# cslr_usb_001 register map
Vendor: Texas Instruments
Registers are 32-bit, access not given, reset values left out (the file's numbers can be read two ways) unless marked. A register's access mark holds for its fields unless they carry their own. Offsets are as the file gives them; [hi:lo] are bit positions; {n}, {i} and the like mark numbered series; 'fields as' and 'values as' point back to an identical list.

## USB (part 2 of 2) — USB2.0 OTG Controller
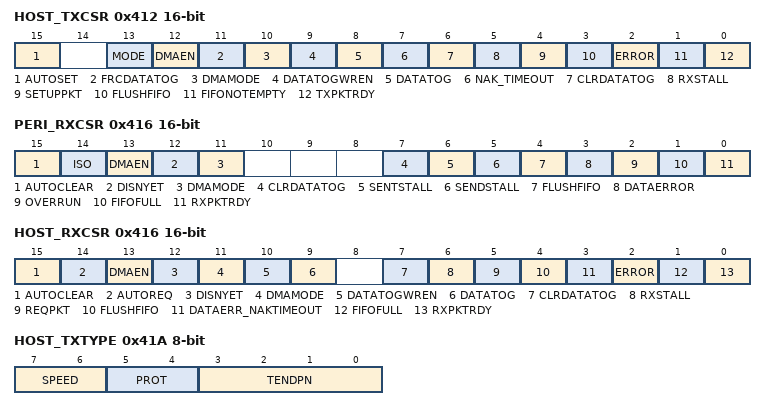
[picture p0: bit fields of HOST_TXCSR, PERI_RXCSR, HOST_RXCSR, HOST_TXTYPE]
0x412 HOST_TXCSR 16-bit — Control Status register for host Tx endpoint. (Index register set to select Endpoints 1 - 4)
  [15] AUTOSET rw — When this bit is set, TXPKTRDY will be automatically set when data of the maximum packet size (value in TXMAXP) is loaded into the Tx FIFO. If a packet of less than the maximum packet size is loaded, then TXPKTRDY will have to be set manually. TXPKTRDY will also be automatically set when the first of two packets in the Tx FIFO has been sent and the second packet is the maximum packet size
  [13] MODE rw — Set this bit to enable the endpoint direction as Tx, and clear the bit to enable it as Rx Note: This bit has any effect only where the same endpoint FIFO is used for both Tx and Rx transactions
  [12] DMAEN rw — Set this bit to enable the DMA request for the Tx endpoint
  [11] FRCDATATOG rw — Set this bit to force the endpoint data toggle to switch and the data packet to be cleared from the FIFO, regardless of whether an ACK was received. This can be used by Interrupt Tx endpoints that are used to communicate rate feedback for Isochronous endpoints
  [10] DMAMODE rw — This bit should always be 0
  [9] DATATOGWREN wo — Write 1 to this bit to enable the DATATOG bit to be written. This bit is automatically cleared once the new value is written to DATATOG
  [8] DATATOG rw — When read, this bit indicates the current state of the Tx EP data toggle. If DATATOGWREN is high, this bit canbe written with the required setting of the data toggle. If DATATOGWREN is low, any value written to this bit is ignored
  [7] NAK_TIMEOUT rw — This bit will be set when the Tx endpoint is halted following the receipt of NAK responses for longer than the time set as the NAKLIMIT by the TXINTERVAL register. It should be cleared to allow the endpoint to continue Note: Valid only for Bulk endpoints
  [6] CLRDATATOG wo — Write a 1 to this bit to reset the endpoint data toggle to 0
  [5] RXSTALL rw — This bit is set when a STALL handshake is received. The FIFO is flushed and the TXPKTRDY bit is cleared (see below). The user should clear this bit
  [4] SETUPPKT rw — Set this bit at the sametime as TXPKTRDY is set, to send a SETUP token instead of an OUT token for the transaction. Note: Setting this bit also clears DATATOG bit
  [3] FLUSHFIFO wo — Write a 1 to this bit to flush the next packet to be transmitted from the endpoint Tx FIFO. The FIFO pointer is reset and the TXPKTRDY bit (below) is cleared. Note: FlushFIFO has no effect unless TXPKTRDY is set. Also note that, if the FIFO is double-buffered, FLUSHFIFO may need to be set twice to completely clear the FIFO
  [2] ERROR rw — The USB controller sets this bit when 3 attempts have been made to send a packet and no handshake packet has been received. The user should clear this bit. An interrupt is generated when the bit is set Valid only when the endpoint is operating in Bulk or Interrupt mode
  [1] FIFONOTEMPTY rw — The USB controller sets this bit when there is at least 1 packet in the Tx FIFO
  [0] TXPKTRDY rw — Set this bit after loading a data packet into the FIFO. It is cleared automatically when a data packet has been transmitted. An interrupt is generated (if enabled) when the bit is cleared
0x414 RXMAXP 16-bit — Maximum packet size for peripheral/host Rx endpoint (Index register set to select Endpoints 1 - 4 only)
  [10:0] MAXPAYLOAD rw — Defines the maximum amount of data that can be transferred through the selected Rx endpoint in a single frame / microframe (High-speed transfers) The value set can be up to 1024 bytes but is subject to the constraints placed by the USB Specification on packet sizes for Bulk, Interrupt and Isochronous transfers in Full-speed and High-speed operations The value written to this register should match the wMaxPacketSize field of the Standard Endpoint Descriptor for the associated endpoint. A mismatch could cause unexpected results
0x416 PERI_RXCSR 16-bit — Control Status register for peripheral Rx endpoint. (Index register set to select Endpoints 1 - 4)
  [15] AUTOCLEAR rw — When this bit is set, the RXPKTRDY bit will be automatically cleared when a packet of RXMAXP bytes has been unloaded from the Rx FIFO. When packets of less than the maximum packet size are unloaded, RXPKTRDY will have to be cleared manually
  [14] ISO rw — Set this bit to enable the Rx endpoint for Isochronous transfers, and clear it to enable the Rx endpoint for Bulk/Interrupt transfers
  [13] DMAEN rw — Set this bit to enable the DMA request for the Rx endpoints
  [12] DISNYET rw — Set this bit to disable the sending of NYET handshakes. When set, all successfully received Rx packets are ACK'd including at the point at which the FIFO becomes full Note: This bit only has any effect in High-speed mode, in which mode it should be set for all Interrupt endpoints
  [11] DMAMODE rw — This bit should always be 0
  [7] CLRDATATOG wo — Write a 1 to this bit to reset the endpoint data toggle to 0
  [6] SENTSTALL rw — This bit is set when a STALL handshake is transmitted. The FIFO is flushed and the TXPKTRDY bit is cleared (see below). The user should clear this bit
  [5] SENDSTALL rw — Write a 1 to this bit to issue a STALL handshake Clear this bit to terminate the stall condition Note: This bit has no effect where the endpoint is being used for Isochronous transfers
  [4] FLUSHFIFO wo — Write a 1 to this bit to flush the next packet to be read from the endpoint Rx FIFO. The FIFO pointer is reset and the RXPKTRDY bit (below) is cleared Note: FLUSHFIFO has no effect unless RXPKTRDY is set. Also note that, if the FIFO is double-buffered, FLUSHFIFO may need to be set twice to completely clear the FIFO
  [3] DATAERROR ro — This bit is set when RXPKTRDY is set if the data packet has a CRC or bit-stuff error. It is cleared when RXPKTRDY is cleared Note: This bit is only valid when the endpoint is operating in ISO mode. In Bulk mode, it always returns zero.
  [2] OVERRUN rw — This bit is set if an OUT packet cannot be loaded into the Rx FIFO. The user should clear this bit Note: This bit is only valid when the endpoint is operating in ISO mode. In Bulk mode, it always returns zero
  [1] FIFOFULL ro — This bit is set when no more packets can be loaded into the Rx FIFO
  [0] RXPKTRDY rw — This bit is set when a data packet has been received. The user should clear this bit when the packet has been unloaded from the Rx FIFO. An interrupt is generated when the bit is set
0x416 HOST_RXCSR 16-bit — Control Status register for host Rx endpoint. (Index register set to select Endpoints 1 - 4)
  [15] AUTOCLEAR rw — When this bit is set, the RXPKTRDY bit will be automatically cleared when a packet of RXMAXP bytes has been unloaded from the Rx FIFO. When packets of less than the maximum packet size are unloaded, RXPKTRDY will have to be cleared manually
  [14] AUTOREQ rw — When this bit is set, the REQPKT bit will be automatically set when the RXPKTRDY bit is cleared
  [13] DMAEN rw — Set this bit to enable the DMA request for the Rx endpoints
  [12] DISNYET rw — Set this bit to disable the sending of NYET handshakes. When set, all successfully received Rx packets are ACK'd including at the point at which the FIFO becomes full Note: This bit only has any effect in High-speed mode, in which mode it should be set for all Interrupt endpoints
  [11] DMAMODE rw — This bit should always be 0
  [10] DATATOGWREN wo — Write 1 to this bit to enable the DATATOG bit to be written. This bit is automatically cleared once the new value is written to DATATOG
  [9] DATATOG rw — When read, this bit indicates the current state of the Rx EP data toggle. If DATATOGWREN is high, this bit canbe written with the required setting of the data toggle. If DATATOGWREN is low, any value written to this bit is ignored
  [7] CLRDATATOG wo — Write a 1 to this bit to reset the endpoint data toggle to 0
  [6] RXSTALL rw — When a STALL handshake is received, this bit is set and an interrupt is generated. The user should clear this bit
  [5] REQPKT rw — Write a 1 to this bit to request an IN transaction. It is cleared when RXPKTRDY is set
  [4] FLUSHFIFO wo — Write a 1 to this bit to flush the next packet to be read from the endpoint Rx FIFO. The FIFO pointer is reset and the RXPKTRDY bit (below) is cleared Note: FLUSHFIFO has no effect unless RXPKTRDY is set. Also note that, if the FIFO is double-buffered, FLUSHFIFO may need to be set twice to completely clear the FIFO
  [3] DATAERR_NAKTIMEOUT ro — When operating in ISO mode, this bit is set when RXPKTRDY is set if the data packet has a CRC or bit-stuff error and cleared when RXPKTRDY is cleared In Bulk mode, this bit will be set when the Rx endpoint is halted following the receipt of NAK responses for longer than the time set as the NAK Limit by the RXINTERVAL register. The user should clear this bit to allow the endpoint to continue
  [2] ERROR rw — The USB controller sets this bit when 3 attempts have been made to receive a packet and no data packet has been received. The user should clear this bit. An interrupt is generated when the bit is set Note: This bit is only valid when the Tx endpoint is operating in Bulk or Interrupt mode. In ISO mode, it always returns zero
  [1] FIFOFULL ro — This bit is set when no more packets can be loaded into the Rx FIFO
  [0] RXPKTRDY rw — This bit is set when a data packet has been received. The user should clear this bit when the packet has been unloaded from the Rx FIFO. An interrupt is generated when the bit is set
0x418 COUNT0 16-bit — Number of received bytes in Endpoint 0 FIFO. (Index register set to select Endpoint 0)
  [6:0] EP0RXCOUNT ro — Indicates the number of received data bytes in the Endpoint 0 FIFO The value returned changes as the contents of the FIFO change and is only valid while RXPKTRDY of PERI_CSR0 or HOST_CSR0 is set
0x418 RXCOUNT 16-bit — Number of bytes in host Rx endpoint FIFO. (Index register set to select Endpoints 1 - 4)
  [12:0] EPRXCOUNT ro — Holds the number of received data bytes in the packet in the Rx FIFO The value returned changes as the contents of the FIFO change and is only valid while RXPKTRDY of PERI_RXCSR or HOST_RXCSR is set
0x41A HOST_TYPE0 8-bit — Defines the speed of Endpoint 0
  [7:6] SPEED rw — Operating Speed of Target Device 00: Illegal 01: High 10: Full 11: Low
0x41A HOST_TXTYPE 8-bit rw — Sets the operating speed, transaction protocol and peripheral endpoint number for the host Tx endpoint. (Index register set to select Endpoints 1 - 4 only)
  [7:6] SPEED — Operating Speed of Target Device 00: Illegal 01: High 10: Full 11: Low
  [5:4] PROT — Set this to select the required protocol for the Tx endpoint 00: Control 01: Isochronous 10: Bulk 11: Interrupt
  [3:0] TENDPN — Set this value to the endpoint number contained in the Tx endpoint descriptor returned to the USB controller during device enumeration
0x41B HOST_NAKLIMIT0 8-bit — Sets the NAK response timeout on Endpoint 0. (Index register set to select Endpoint 0)
  [4:0] EP0NAKLIMIT rw — Sets the number of frames/microframes (High-Speed transfers) after which Endpoint 0 should timeout on receiving a stream of NAK responses The number of frames/microframes selected is 2 ( m -1) (where m is the value set in the register, valid values 2 - 16). If the host receives NAK responses from the target for more frames than the number represented by the Limit set in this register, the endpoint will be halted Note: A value of 0 or 1 disables the NAK timeout function
0x41B HOST_TXINTERVAL 8-bit rw — Sets the polling interval for Interrupt/ISOC transactions or the NAK response timeout on Bulk transactions for host Tx endpoint. (Index register set to select Endpoints 1 - 4 only)
  [7:0] POLINTVL_NAKLIMIT — For Interrupt and Isochronous transfers, defines the polling interval for the currently-selected Tx endpoint For Bulk endpoints, this register sets the number of frames/microframes after which the endpoint should timeout on receiving a stream of NAK responses There is a TxInterval register for each configured Tx endpoint (except Endpoint 0). In each case the value that is set defines a number of frames/microframes (High Speed transfers), as follows ----------------------------------------------------------------------------------------------------------------------------------------------------------------- Transfer Type Speed Valid values (m) Interpretation ----------------------------------------------------------------------------------------------------------------------------------------------------------------- Interrupt Low Speed or Full Speed 1 - 255 Polling interval is m frames High Speed 1 - 16 Polling interval is 2 ( m -1) microframes ------------------------------------------------------------------------------------------------------------------------------------------------------------------ Isochronous Full Speed or High Speed 1 - 16 Polling interval is 2 ( m -1) frames/microframes ------------------------------------------------------------------------------------------------------------------------------------------------------------------- Bulk Full Speed or High Speed 2 - 16 NAK Limit is 2 ( m-1) frames/microframes Note: A value of 0 or 1 disables the NAK timeout function ------------------------------------------ -------------------------------------------------------------------------------------------------------------------------
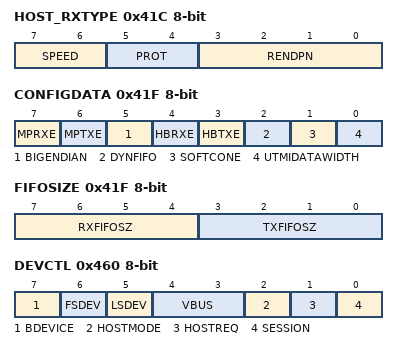
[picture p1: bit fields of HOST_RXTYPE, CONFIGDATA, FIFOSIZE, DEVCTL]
0x41C HOST_RXTYPE 8-bit rw — Sets the operating speed, transaction protocol and peripheral endpoint number for the host Rx endpoint. (Index register set to select Endpoints 1 - 4 only)
  [7:6] SPEED — Operating Speed of Target Device 00: Illegal 01: High 10: Full 11: Low
  [5:4] PROT — The CPU should set this to select the required protocol for the Rx endpoint 00: Control 01: Isochronous 10: Bulk 11: Interrupt
  [3:0] RENDPN — Set this value to the endpoint number contained in the Rx endpoint descriptor returned to the USB Controller during device enumeration
0x41D HOST_RXINTERVAL 8-bit rw — Sets the polling interval for Interrupt/ISOC transactions or the NAK response timeout on Bulk transactions for host Rx endpoint. (Index register set to select Endpoints 1 - 4 only)
  [7:0] POLINTVL_NAKLIMIT — For Interrupt and Isochronous transfers, defines the polling interval for the currently-selected Rx endpoint For Bulk endpoints, this register sets the number of frames/microframes after which the endpoint should timeout on receiving a stream of NAK responses There is a RxInterval register for each configured Rx endpoint (except Endpoint 0).In each case the value that is set defines a number of frames/microframes (High Speed transfers), as follows ----------------------------------------------------------------------------------------------------------------------------------------------------------------- Transfer Type Speed Valid values (m) Interpretation ----------------------------------------------------------------------------------------------------------------------------------------------------------------- Interrupt Low Speed or Full Speed 1 - 255 Polling interval is m frames High Speed 1 - 16 Polling interval is 2 ( m -1) microframes ------------------------------------------------------------------------------------------------------------------------------------------------------------------ Isochronous Full Speed or High Speed 1 - 16 Polling interval is 2 ( m -1) frames/microframes ------------------------------------------------------------------------------------------------------------------------------------------------------------------- Bulk Full Speed or High Speed 2 - 16 NAK Limit is 2 ( m-1) frames/microframes Note: A value of 0 or 1 disables the NAK timeout function ------------------------------------------- ------------------------------------------------------------------------------------------------------------------------
0x41F CONFIGDATA 8-bit — Returns details of core configuration (Index register set to select Endpoint 0)
  [7] MPRXE — When set to '1', automatic amalgamation of bulk packets is selected (access N)
  [6] MPTXE ro — When set to '1', automatic splitting of bulk packets is selected
  [5] BIGENDIAN ro — When set to '1' indicates Big Endian ordering is selected
  [4] HBRXE ro — When set to '1' indicates High-bandwidth Rx ISO Endpoint Support selected
  [3] HBTXE ro — When set to '1' indicates High-bandwidth Tx ISO Endpoint Support selected
  [2] DYNFIFO ro — When set to '1' indicates Dynamic FIFO Sizing option selected
  [1] SOFTCONE ro — When set to '1' indicates Soft Connect/Disconnect option selected
  [0] UTMIDATAWIDTH ro — Indicates selected UTMI data width 0: 8 bits 1: 16 bits
0x41F FIFOSIZE 8-bit ro — Returns the configured size of the selected Rx FIFO and Tx FIFOs (Endpoints 1 - 4 only)
  [7:4] RXFIFOSZ — Returns the sizes of the FIFOs associated with the selected Rx endpoints Values of 3 - 13 correspond to a FIFO size of 2n bytes (8 - 8192 bytes). If an endpoint has not been configured, a value of 0 will be displayed When the Tx and Rx endpoints share the same FIFO, the Rx FIFO size will be encoded as 15 Note: The register only has this interpretation when the Index register is set to select one of Endpoints 1 - 4 and Dynamic Sizing is not selected
  [3:0] TXFIFOSZ — Returns the sizes of the FIFOs associated with the selected Tx endpoints Values of 3 - 13 correspond to a FIFO size of 2n bytes (8 - 8192 bytes). If an endpoint has not been configured, a value of 0 will be displayed Note: The register only has this interpretation when the Index register is set to select one of Endpoints 1 - 4 and Dynamic Sizing is not selected
{0x420+4i} FIFO{i} rw (i=0..4) — Tx and Rx FIFO register for Endpoint {i}
  [31:0] DATA — Writing to these addresses loads data into the TxFIFO for the corresponding endpoint Reading from these addresses unloads data from the RxFIFO for the corresponding endpoint
0x460 DEVCTL 8-bit access per field — OTG device control register
  [7] BDEVICE ro — This Read-only bit indicates whether the USB controller is operating as the 'A' device or the 'B' device 0: 'A' device 1: 'B' device Only valid while a session is in progress
  [6] FSDEV ro — This Read-only bit is set when a full-speed or high-speed device has been detected being connected to the port (High-speed devices are distinguished from full-speed by checking for high-speed chirps when the device is reset) Only valid in Host mode
  [5] LSDEV ro — This Read-only bit is set when a low-speed device has been detected being connected to the port Only valid in Host mode
  [4:3] VBUS ro — These Read-only bits encode the current VBus level as follows ----------------------------------------------------------------------------- VBus[1] VBus[0] Meaning ------------------------------------------------------------------------------ 0 0 Below SessionEnd 0 1 Above SessionEnd, below AValid 1 0 Above AValid, below VBusValid 1 1 Above VBusValid
  [2] HOSTMODE ro — This Read-only bit is set when the USB controller is acting as a Host
  [1] HOSTREQ rw — When set, the USB controller will initiate the Host Negotiation when Suspend mode is entered. It is cleared when Host Negotiation is completed. ('B' device only)
  [0] SESSION rw — When operating as an 'A' device, this bit is set or cleared by the userto start or end a session When operating as a 'B' device, this bit is set/cleared by the USB controller when a session starts/ends It is also set by the user to initiate the Session Request Protocol. When the USB controller is in Suspend mode, the bit may be cleared by the user to perform a software disconnect
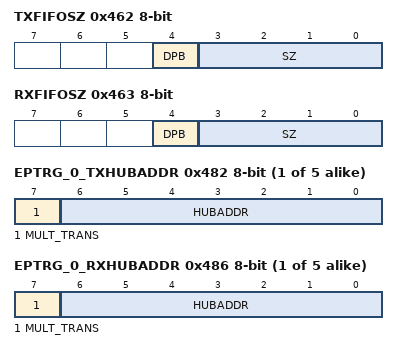
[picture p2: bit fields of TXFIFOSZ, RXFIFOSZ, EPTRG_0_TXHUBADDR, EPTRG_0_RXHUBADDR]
0x462 TXFIFOSZ 8-bit — Tx Endpoint FIFO Size(Index register set to select Endpoints 0 - 4 only)
  [4] DPB rw — When bit is set to '1', double packet buffering is enabled When bit is set to '0', single packet buffering is supported
  [3:0] SZ ro — Maximum packet size to be allowed(before any splitting within the FIFO of Bulk packets prior to transmission) If m = SZ[3:0], the FIFO size is calculated as 2(m+3) for single packet buffering and 2(m+4) for dual packet buffering
0x463 RXFIFOSZ 8-bit — Rx Endpoint FIFO Size(Index register set to select Endpoints 0 - 4 only)
  fields as TXFIFOSZ
0x464 TXFIFOADDR 16-bit — Tx Endpoint FIFO Address(Index register set to select Endpoints 0 - 4 only)
  [12:0] ADDR rw — Start Address of endpoint FIFO in units of 8 bytes If m = ADDR[12:0] then the start address is 8*m
0x466 RXFIFOADDR 16-bit — Rx Endpoint FIFO Address(Index register set to select Endpoints 0 - 4 only)
  fields as TXFIFOADDR
{0x480+8i} EPTRG_{i}_TXFUNCADDR 8-bit (i=0..4) — Address of the target function that has to be accessed through the associated Tx Endpoint
  [6:0] FUNCADDR rw — Address of target function
{0x482+8i} EPTRG_{i}_TXHUBADDR 8-bit rw (i=0..4) — Address of the hub that has to be accessed through the associated Tx Endpoint. This is used only when full speed or low speed device is connected via a USB2.0 high speed hub
  [7] MULT_TRANS — Set to '1' if hub has multiple transaction translators. Set to '0' if only single transaction translator is available
  [6:0] HUBADDR — Address of hub
{0x483+8i} EPTRG_{i}_TXHUBPORT 8-bit (i=0..4) — Port of the hub that has to be accessed through the associated Tx Endpoint. This is used only when full speed or low speed device is connected via a USB2.0 high speed hub
  [6:0] HUBPORT rw — Port number of the hub
{0x484+8i} EPTRG_{i}_RXFUNCADDR 8-bit (i=0..4) — Address of the target function that has to be accessed through the associated Rx Endpoint
  [6:0] FUNCADDR rw — Address of target function
{0x486+8i} EPTRG_{i}_RXHUBADDR 8-bit rw (i=0..4) — Address of the hub that has to be accessed through the associated Rx Endpoint. This is used only when full speed or low speed device is connected via a USB2.0 high speed hub
  fields as EPTRG_0_TXHUBADDR
{0x487+8i} EPTRG_{i}_RXHUBPORT 8-bit (i=0..4) — Port of the hub that has to be accessed through the associated Rx Endpoint. This is used only when full speed or low speed device is connected via a USB2.0 high speed hub
  [6:0] HUBPORT rw — Port number of the hub
{0x500+0x10*i} EPCSR_{i}_TXMAXP 16-bit (i=0..4) — Maximum packet size for peripheral/host Tx endpoint
  [10:0] MAXPAYLOAD rw — The maximum payload transmitted in a single transaction The value set can be up to 1024 bytes but is subject to the constraints placed by the USB Specification on packet sizes for Bulk, Interrupt and Isochronous transfers in Full-speed and High-speed operations The value written to this register should match the wMaxPacketSize field of the Standard Endpoint Descriptor for the associated endpoint. A mismatch could cause unexpected results
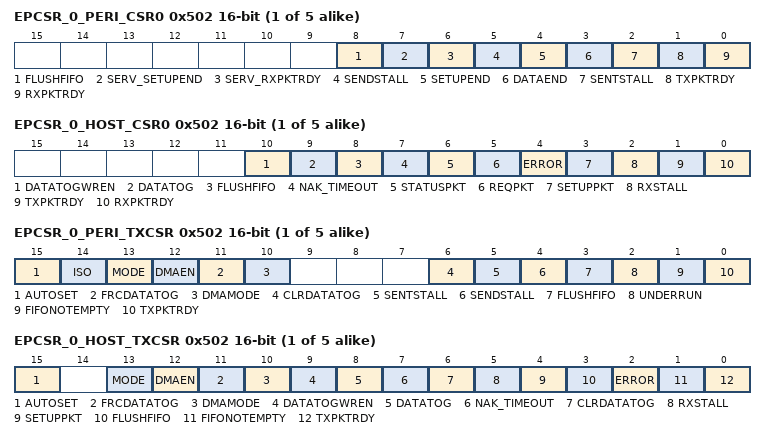
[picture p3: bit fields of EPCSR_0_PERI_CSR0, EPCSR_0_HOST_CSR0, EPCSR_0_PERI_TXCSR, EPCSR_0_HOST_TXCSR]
{0x502+0x10*i} EPCSR_{i}_PERI_CSR0 16-bit (i=0..4) — Control Status register for Endpoint 0 in Peripheral mode.
  [8] FLUSHFIFO wo — Set this bit to flush the next packet to be transmitted/read from the Endpoint 0 FIFO. The FIFO pointer is reset and the TXPKTRDY/RXPKTRDY bit (below) is cleared Note: FLUSHFIFO has no effect unless TXPKTRDY/RXPKTRDY is set
  [7] SERV_SETUPEND wo — Set this bit to clear the SETUPEND bit. It is cleared automatically
  [6] SERV_RXPKTRDY wo — Set this bit to clear the RXPKTRDY bit. It is cleared automatically
  [5] SENDSTALL wo — Set this bit to terminate the current transaction. The STALL handshake will be transmitted and then this bit will be cleared automatically
  [4] SETUPEND ro — This bit will be set when a control transaction ends before the DATAEND bit has been set. An interrupt will be generated and the FIFO flushed at this time. The bit is cleared by the user writing a 1 to the SERV_SETUPEND bit
  [3] DATAEND wo — Set this bit 1. When setting TXPKTRDY for the last data packet 2. When clearing RXPKTRDY after unloading the last data packet 3. When setting TXPKTRDY for a zero length data packet It is cleared automatically
  [2] SENTSTALL rw — This bit is set when a STALL handshake is transmitted. This bit should be cleared by the user
  [1] TXPKTRDY rw — Set this bit after loading a data packet into the FIFO. It is cleared automatically when the data packet has been transmitted. An interrupt is generated (if enabled) when the bit is cleared
  [0] RXPKTRDY ro — This bit is set when a data packet has been received. An interrupt is generated when this bit is set. This bit is cleared by setting the SERV_RXPKTRDY bit
{0x502+0x10*i} EPCSR_{i}_HOST_CSR0 16-bit (i=0..4) — Control Status register for Endpoint 0 in Host mode.
  [10] DATATOGWREN wo — Write 1 to this bit to enable the DATATOG bit to be written. This bit is automatically cleared once the new value is written to DATATOG
  [9] DATATOG rw — When read, this bit indicates the current state of the EP0 data toggle. If DATATOGWREN is high, this bit canbe written with the required setting of the data toggle. If DATATOGWREN is low, any value written to this bit is ignored
  [8] FLUSHFIFO wo — Write 1 to this bit to flush the next packet to be transmitted/read from the Endpoint 0 FIFO. The FIFO pointer is reset and the TXPKTRDY/RXPKTRDY bit (below) is cleared Note: FLUSHFIFO has no effect unless TXPKTRDY/RXPKTRDY is set
  [7] NAK_TIMEOUT wo — This bit will be set when Endpoint 0 is halted following the receipt of NAK responses for longer than the time set by the NAKLIMIT0 register. This bit should be cleared to allow the endpoint to continue
  [6] STATUSPKT rw — Set this bit at the same time as the TXPKTRDY or REQPKT bit is set, to perform a status stage transaction. Setting this bit ensures that the data toggle is set to 1 so that a DATA1 packet is used for the Status Stage transaction
  [5] REQPKT rw — Set this bit to request an IN transaction. It is cleared when RXPKTRDY is set
  [4] ERROR wo — This bit will be set when three attempts have been made to perform a transaction with no response from the peripheral. The user should clear this bit. An interrupt is generated when this bit is set
  [3] SETUPPKT rw — Set this bit, at the same time as the TXPKTRDY bit is set, to send a SETUP token instead of an OUT token for the transaction
  [2] RXSTALL rw — This bit is set when a STALL handshake is received. The user should clear this bit
  [1] TXPKTRDY rw — Set this bit after loading a data packet into the FIFO. It is cleared automatically when the data packet has been transmitted. An interrupt is generated (if enabled) when the bit is cleared
  [0] RXPKTRDY rw — This bit is set when a data packet has been received. An interrupt is generated when this bit is set. Clear this bit by setting the SERV_RXPKTRDY bit
{0x502+0x10*i} EPCSR_{i}_PERI_TXCSR 16-bit (i=0..4) — Control Status register for peripheral Tx endpoint.
  [15] AUTOSET rw — When this bit is set, TXPKTRDY will be automatically set when data of the maximum packet size (value in TXMAXP is loaded into the Tx FIFO. If a packet of less than the maximum packet size is loaded, then TXPKTRDY will have to be set manually. TXPKTRDY will also be automatically set when the first of two packets in the Tx FIFO has been sent and the second packet is the maximum packet size
  [14] ISO rw — Set this bit to enable the Tx endpoint for Isochronous transfers, and clear it to enable the Tx endpoint for Bulk or Interrupt transfers
  [13] MODE rw — Set this bit to enable the endpoint direction as Tx, and clear the bit to enable it as Rx Note: This bit only has any effect where the same endpoint FIFO is used for both Tx and Rx transactions
  [12] DMAEN rw — Set this bit to enable the DMA request for the Tx endpoint
  [11] FRCDATATOG rw — Set this bit to force the endpoint data toggle to switch and the data packet to be cleared from the FIFO, regardless of whether an ACK was received. This can be used by Interrupt Tx endpoints that are used to communicate rate feedback for Isochronous endpoints
  [10] DMAMODE rw — This bit should always be 0
  [6] CLRDATATOG wo — Write a 1 to this bit to reset the endpoint data toggle to 0
  [5] SENTSTALL rw — This bit is set automatically when a STALL handshake is transmitted. The FIFO is flushed and the TXPKTRDY bit is cleared (see below). The user should clear this bit
  [4] SENDSTALL rw — Write a 1 to this bit to issue a STALL handshake to an IN token. Clear this bit to terminate the stall condition Note: This bit has no effect where the endpoint is being used for Isochronous transfers
  [3] FLUSHFIFO wo — Write a 1 to this bit to flush the next packet to be transmitted from the endpoint Tx FIFO. The FIFO pointer is reset and the TXPKTRDY bit (below) is cleared. Note: FlushFIFO has no effect unless TXPKTRDY is set. Also note that, if the FIFO is double-buffered, FlushFIFO may need to be set twice to completely clear the FIFO
  [2] UNDERRUN rw — This bit is set automatically if an IN token is received when TXPKTRDY is not set. The user should clear this bit
  [1] FIFONOTEMPTY rw — This bit is set when there is at least 1 packet in the Tx FIFO. The user should clear this bit
  [0] TXPKTRDY rw — Set this bit after loading a data packet into the FIFO. It is cleared automatically when a data packet has been transmitted. An interrupt is generated (if enabled) when the bit is cleared
{0x502+0x10*i} EPCSR_{i}_HOST_TXCSR 16-bit (i=0..4) — Control Status register for host Tx endpoint.
  fields as HOST_TXCSR
{0x504+0x10*i} EPCSR_{i}_RXMAXP 16-bit (i=0..4) — Maximum packet size for peripheral/host Rx endpoint
  fields as RXMAXP
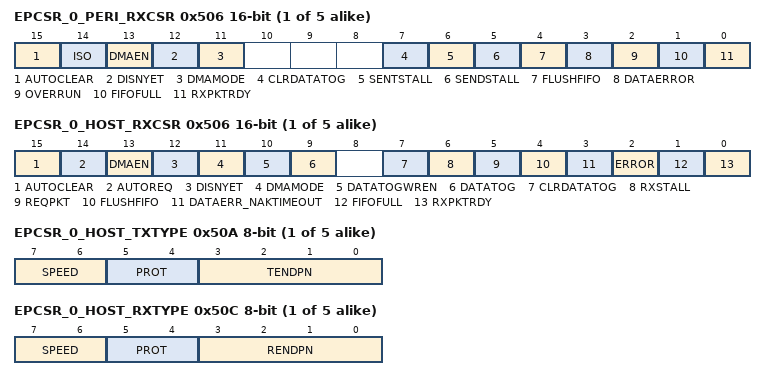
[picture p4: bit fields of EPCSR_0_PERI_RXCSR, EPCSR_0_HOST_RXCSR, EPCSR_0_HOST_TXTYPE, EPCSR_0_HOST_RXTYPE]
{0x506+0x10*i} EPCSR_{i}_PERI_RXCSR 16-bit (i=0..4) — Control Status register for peripheral Rx endpoint.
  fields as PERI_RXCSR
{0x506+0x10*i} EPCSR_{i}_HOST_RXCSR 16-bit (i=0..4) — Control Status register for host Rx endpoint.
  fields as HOST_RXCSR
{0x508+0x10*i} EPCSR_{i}_COUNT0 16-bit (i=0..4) — Number of received bytes in Endpoint 0 FIFO.
  fields as COUNT0
{0x508+0x10*i} EPCSR_{i}_RXCOUNT 16-bit (i=0..4) — Number of bytes in host Rx endpoint FIFO.
  fields as RXCOUNT
{0x50A+0x10*i} EPCSR_{i}_HOST_TYPE0 8-bit (i=0..4) — Defines the speed of Endpoint 0
  fields as HOST_TYPE0
{0x50A+0x10*i} EPCSR_{i}_HOST_TXTYPE 8-bit rw (i=0..4) — Sets the operating speed, transaction protocol and peripheral endpoint number for the host Tx endpoint.
  fields as HOST_TXTYPE
{0x50B+0x10*i} EPCSR_{i}_HOST_NAKLIMIT0 8-bit (i=0..4) — Sets the NAK response timeout on Endpoint 0.
  fields as HOST_NAKLIMIT0
{0x50B+0x10*i} EPCSR_{i}_HOST_TXINTERVAL 8-bit rw (i=0..4) — Sets the polling interval for Interrupt/ISOC transactions or the NAK response timeout on Bulk transactions for host Tx endpoint.
  [7:0] POLINTVL_NAKLIMIT — For Interrupt and Isochronous transfers, defines the polling interval for the currently-selected Tx endpoint For Bulk endpoints, this register sets the number of frames/microframes after which the endpoint should timeout on receiving a stream of NAK responses There is a TxInterval register for each configured Tx endpoint (except Endpoint 0). In each case the value that is set defines a number of frames/microframes (High Speed transfers), as follows ----------------------------------------------------------------------------------------------------------------------------------------------------------------- Transfer Type Speed Valid values (m) Interpretation ----------------------------------------------------------------------------------------------------------------------------------------------------------------- Interrupt Low Speed or Full Speed 1 - 255 Polling interval is m frames High Speed 1 - 16 Polling interval is 2 ( m -1) microframes ------------------------------------------------------------------------------------------------------------------------------------------------------------------ Isochronous Full Speed or High Speed 1 - 16 Polling interval is 2 ( m -1) frames/microframes ------------------------------------------------------------------------------------------------------------------------------------------------------------------- Bulk Full Speed or High Speed 2 - 16 NAK Limit is 2 ( m-1) frames/microframes Note: A value of 0 or 1 disables the NAK timeout function -------------------------------------- -----------------------------------------------------------------------------------------------------------------------------
{0x50C+0x10*i} EPCSR_{i}_HOST_RXTYPE 8-bit rw (i=0..4) — Sets the operating speed, transaction protocol and peripheral endpoint number for the host Rx endpoint.
  fields as HOST_RXTYPE
{0x50D+0x10*i} EPCSR_{i}_HOST_RXINTERVAL 8-bit rw (i=0..4) — Sets the polling interval for Interrupt/ISOC transactions or the NAK response timeout on Bulk transactions for host Rx endpoint.
  [7:0] POLINTVL_NAKLIMIT — For Interrupt and Isochronous transfers, defines the polling interval for the currently-selected Rx endpoint For Bulk endpoints, this register sets the number of frames/microframes after which the endpoint should timeout on receiving a stream of NAK responses There is a RxInterval register for each configured Rx endpoint (except Endpoint 0).In each case the value that is set defines a number of frames/microframes (High Speed transfers), as follows ----------------------------------------------------------------------------------------------------------------------------------------------------------------- Transfer Type Speed Valid values (m) Interpretation ----------------------------------------------------------------------------------------------------------------------------------------------------------------- Interrupt Low Speed or Full Speed 1 - 255 Polling interval is m frames High Speed 1 - 16 Polling interval is 2 ( m -1) microframes ------------------------------------------------------------------------------------------------------------------------------------------------------------------ Isochronous Full Speed or High Speed 1 - 16 Polling interval is 2 ( m -1) frames/microframes ------------------------------------------------------------------------------------------------------------------------------------------------------------------- Bulk Full Speed or High Speed 2 - 16 NAK Limit is 2 ( m-1) frames/microframes Note: A value of 0 or 1 disables the NAK timeout function --------------------------------------- ----------------------------------------------------------------------------------------------------------------------------
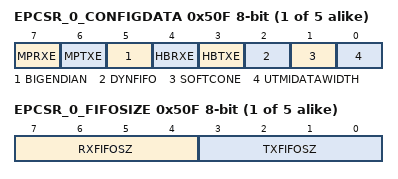
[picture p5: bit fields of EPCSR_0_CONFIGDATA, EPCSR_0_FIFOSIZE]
{0x50F+0x10*i} EPCSR_{i}_CONFIGDATA 8-bit (i=0..4) — Returns details of core configuration
  fields as CONFIGDATA
{0x50F+0x10*i} EPCSR_{i}_FIFOSIZE 8-bit ro (i=0..4) — Returns the configured size of the selected Rx FIFO and Tx FIFOs
  fields as FIFOSIZE
